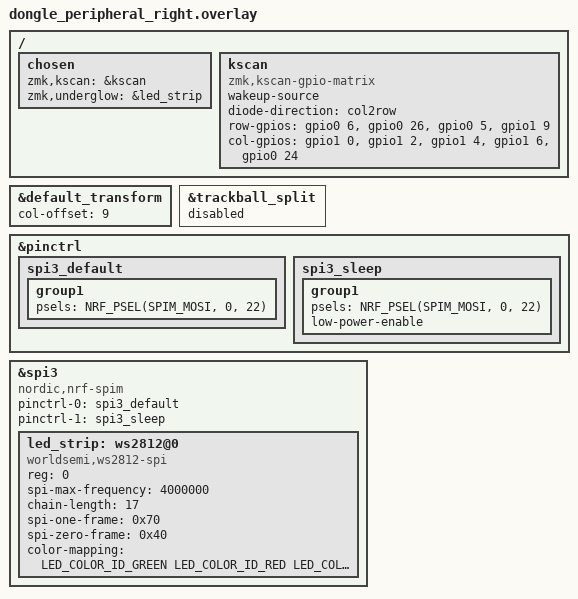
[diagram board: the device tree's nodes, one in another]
#include "dongle.dtsi"
#include "trackball.dtsi"
#include <dt-bindings/led/led.h>

&default_transform {
	col-offset = <9>;
};
&trackball_split {
    status = "disabled";
};

/ {
    chosen {
        zmk,kscan = &kscan;
        zmk,underglow = &led_strip;
    };

    kscan: kscan {
        compatible = "zmk,kscan-gpio-matrix";
        wakeup-source;
        diode-direction = "col2row";
        row-gpios
            = <&gpio0 6 (GPIO_ACTIVE_HIGH | GPIO_PULL_DOWN)>
            , <&gpio0 26 (GPIO_ACTIVE_HIGH | GPIO_PULL_DOWN)>
            , <&gpio0 5 (GPIO_ACTIVE_HIGH | GPIO_PULL_DOWN)>
            , <&gpio1 9 (GPIO_ACTIVE_HIGH | GPIO_PULL_DOWN)>
            ;
        col-gpios
            = <&gpio1 0 GPIO_ACTIVE_HIGH>
            , <&gpio1 2 GPIO_ACTIVE_HIGH>
            , <&gpio1 4 GPIO_ACTIVE_HIGH>
            , <&gpio1 6 GPIO_ACTIVE_HIGH>
            , <&gpio0 24 GPIO_ACTIVE_HIGH>
            ;
    };
};

&pinctrl {
//for ws2812
    spi3_default: spi3_default {
        group1 {
            psels = <NRF_PSEL(SPIM_MOSI, 0, 22)>;
        };
    };

    spi3_sleep: spi3_sleep {
        group1 {
            psels = <NRF_PSEL(SPIM_MOSI, 0, 22)>;
            low-power-enable;
        };
    };
};

//ws2812
&spi3 {
    compatible = "nordic,nrf-spim";
    status = "okay";

    pinctrl-0 = <&spi3_default>;
    pinctrl-1 = <&spi3_sleep>;
    pinctrl-names = "default", "sleep";

    led_strip: ws2812@0 {
        compatible = "worldsemi,ws2812-spi";

        /* SPI */
        reg = <0>; /* ignored, but necessary for SPI bindings */
        spi-max-frequency = <4000000>;

        /* WS2812 */
        chain-length = <17>; /* arbitrary; change at will */
        spi-one-frame = <0x70>;
        spi-zero-frame = <0x40>;
        color-mapping = <LED_COLOR_ID_GREEN
                         LED_COLOR_ID_RED
                         LED_COLOR_ID_BLUE>;
    };
};

